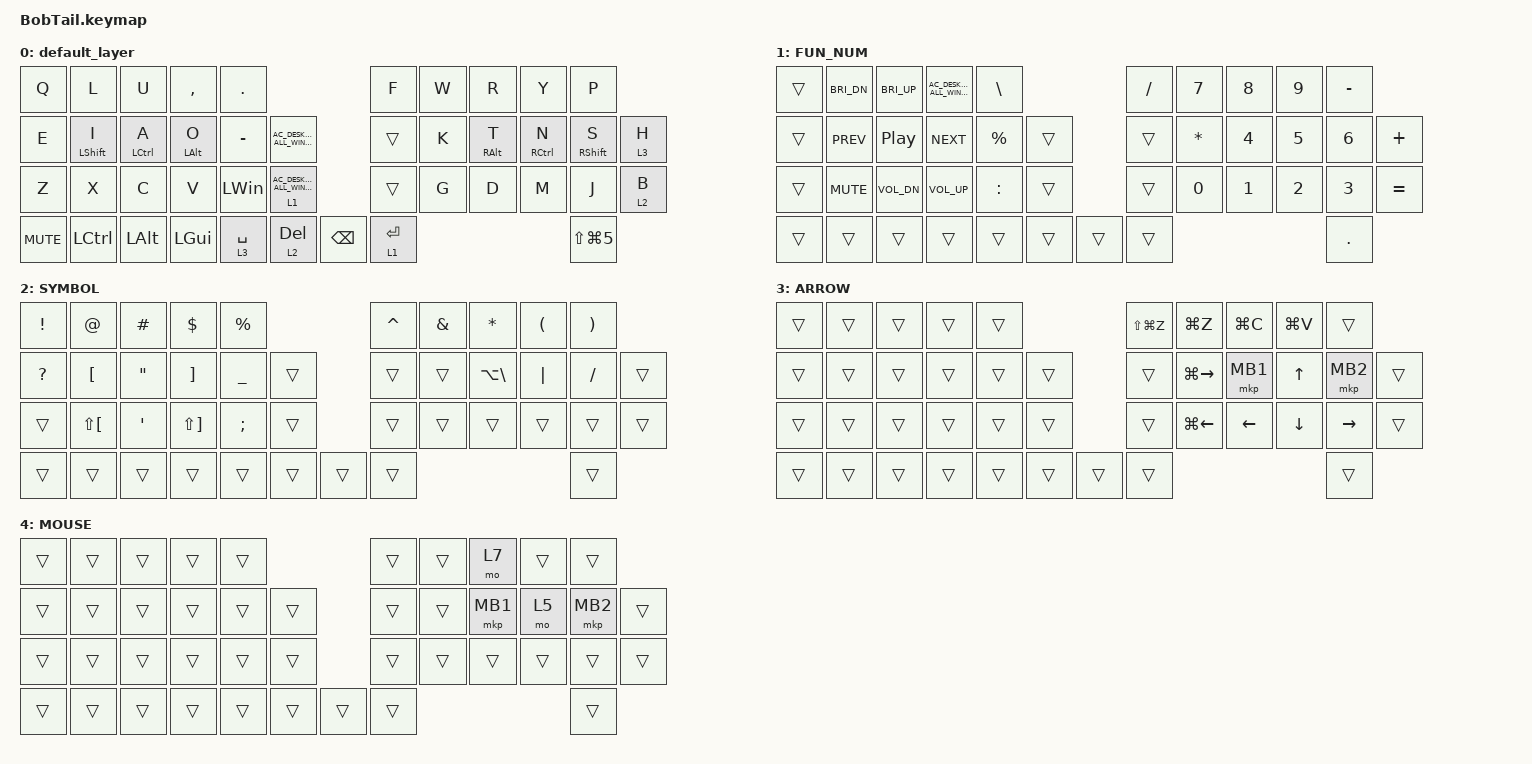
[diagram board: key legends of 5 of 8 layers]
#include <behaviors.dtsi>
#include <dt-bindings/zmk/bt.h>
#include <dt-bindings/zmk/keys.h>
#include <dt-bindings/zmk/pointing.h>

#define MOUSE 4
#define SCROLL 5
#define NUM 6
#define ZMK_POINTING_DEFAULT_SCRL_VAL 80

&mt {
    flavor = "balanced";
    quick-tap-ms = <0>;
};

/ {
    combos {
        compatible = "zmk,combos";

        lang2 {
            bindings = <&kp LANG2>;
            key-positions = <13 12>;
        };

        lang1 {
            bindings = <&kp LANG1>;
            key-positions = <18 19>;
        };

        esc {
            bindings = <&kp ESC>;
            key-positions = <0 1>;
        };

        tab {
            bindings = <&kp TAB>;
            key-positions = <10 11>;
        };

        Bluetooth {
            bindings = <&mo 6>;
            key-positions = <34 35>;
        };
    };

    behaviors {

        encoder_msc_down_up: encoder_msc_down_up {
            compatible = "zmk,behavior-sensor-rotate";
            label = "ENCODER_MSC_DOWN_UP";
            #sensor-binding-cells = <0>;
            bindings = <&msc SCRL_DOWN>, <&msc SCRL_UP>;
            tap-ms = <20>;
        };

        encoder_scroll_v: encoder_scroll_v {
            compatible = "zmk,behavior-sensor-rotate";
            label = "ENCODER_SCROLL_V";
            #sensor-binding-cells = <0>;
            bindings = <&msc SCRL_DOWN>, <&msc SCRL_UP>;
            tap-ms = <20>;
        };

        encoder_volume: encoder_volume {
            compatible = "zmk,behavior-sensor-rotate";
            label = "ENCODER_VOLUME";
            #sensor-binding-cells = <0>;
            bindings = <&kp C_VOL_UP>, <&kp C_VOL_DN>;
            tap-ms = <20>;
        };

        encoder_win_zoom: encoder_win_zoom {
            compatible = "zmk,behavior-sensor-rotate";
            label = "ENCODER_WIN_ZOOM";
            #sensor-binding-cells = <0>;
            /* 右回し→⌘-、左回し→⌘; */
            bindings = <&kp LG(MINUS)>, <&kp LG(SEMI)>;
            tap-ms = <20>;
        };

        encoder_scroll_h: encoder_scroll_h {
            compatible = "zmk,behavior-sensor-rotate";
            label = "ENCODER_SCROLL_H";
            #sensor-binding-cells = <0>;
            /* 右回し→左、左回し→右 */
            /* 縦スクロール80に対して横スクロール160 */
            bindings = <&msc MOVE_X(-160)>, <&msc MOVE_X(160)>;
            tap-ms = <20>;
        };
    };

    keymap {
        compatible = "zmk,keymap";

        default_layer {
            bindings = <
&kp Q       &kp L             &kp U         &kp COMMA       &kp PERIOD                                     &kp F        &kp W            &kp R        &kp Y              &kp P
&kp E       &mt LEFT_SHIFT I  &mt LCTRL A   &mt LEFT_ALT O  &kp MINUS     &kp C_AC_DESKTOP_SHOW_ALL_WINDOWS   &trans         &kp K        &mt RIGHT_ALT T  &mt RCTRL N  &mt RIGHT_SHIFT S  &lt 3 H
&kp Z       &kp X             &kp C         &kp V           &kp LEFT_WIN  &lt 1 C_AC_DESKTOP_SHOW_ALL_WINDOWS  &trans         &kp G        &kp D            &kp M        &kp J              &lt 2 B
&kp C_MUTE  &kp LCTRL         &kp LEFT_ALT  &kp LEFT_GUI    &lt 3 SPACE   &lt 2 DELETE      &kp BACKSPACE  &lt 1 ENTER                                                   &kp LS(LG(N5))
            >;

            sensor-bindings = <&encoder_msc_down_up>;
        };

        FUN_NUM {
            bindings = <
&trans  &kp C_BRI_DN  &kp C_BRI_UP      &kp C_AC_DESKTOP_SHOW_ALL_WINDOWS  &kp BACKSLASH                      &kp SLASH  &kp N7  &kp N8  &kp N9  &kp MINUS
&trans  &kp C_PREV    &kp C_PLAY_PAUSE  &kp C_NEXT                         &kp PRCNT      &trans      &trans  &kp ASTRK  &kp N4  &kp N5  &kp N6  &kp PLUS
&trans  &kp C_MUTE    &kp C_VOL_DN      &kp C_VOL_UP                       &kp COLON      &trans      &trans  &kp N0     &kp N1  &kp N2  &kp N3  &kp EQUAL
&trans  &trans        &trans            &trans                             &trans         &trans      &trans  &trans                             &kp DOT
            >;

            sensor-bindings = <&encoder_volume>;
        };

        SYMBOL {
            bindings = <
&kp EXCL   &kp AT        &kp HASH  &kp DLLR      &kp PRCNT                      &kp CARET  &kp AMPERSAND      &kp STAR  &kp LPAR   &kp RPAR
&kp QMARK  &kp LBKT      &kp DQT   &kp RBKT      &kp UNDER  &trans      &trans  &trans     &kp LA(BACKSLASH)  &kp PIPE  &kp SLASH  &trans
&trans     &kp LS(LBKT)  &kp SQT   &kp LS(RBKT)  &kp SEMI   &trans      &trans  &trans     &trans             &trans    &trans     &trans
&trans     &trans        &trans    &trans        &trans     &trans      &trans  &trans                                             &trans
            >;

            sensor-bindings = <&encoder_win_zoom>;
        };

        ARROW {
            bindings = <
&trans  &trans  &trans  &trans  &trans                      &kp LS(LG(Z))        &kp LG(Z)       &kp LG(C)       &kp LG(V)        &trans
&trans  &trans  &trans  &trans  &trans  &trans      &trans  &kp LG(RIGHT_ARROW)  &mkp MB1        &kp UP_ARROW    &mkp MB2         &trans
&trans  &trans  &trans  &trans  &trans  &trans      &trans  &kp LG(LEFT_ARROW)   &kp LEFT_ARROW  &kp DOWN_ARROW  &kp RIGHT_ARROW  &trans
&trans  &trans  &trans  &trans      &trans          &trans      &trans  &trans                                                                &trans
            >;

            sensor-bindings = <&encoder_scroll_h>;
        };

        MOUSE {
            bindings = <
&trans  &trans  &trans  &trans  &trans                      &trans  &trans    &mo 7   &trans    &trans
&trans  &trans  &trans  &trans  &trans  &trans      &trans  &trans  &mkp MB1  &mo 5   &mkp MB2  &trans
&trans  &trans  &trans  &trans  &trans  &trans      &trans  &trans  &trans    &trans  &trans    &trans
&trans  &trans  &trans  &trans  &trans  &trans      &trans  &trans                              &trans
            >;

            sensor-bindings = <&encoder_scroll_v>;
        };

        SCROLL {
            bindings = <
&trans  &trans  &trans  &trans  &trans                      &trans  &trans  &trans  &trans  &trans
&trans  &trans  &trans  &trans  &trans  &trans      &trans  &trans  &trans  &trans  &trans  &trans
&trans  &trans  &trans  &trans  &trans      &trans  &trans  &trans  &trans  &trans  &trans
&trans  &trans  &trans  &trans  &trans  &trans      &trans  &trans                          &trans
            >;

            sensor-bindings = <&encoder_scroll_v>;
        };

        BLUETOOTH {
            bindings = <
&trans  &trans  &trans  &trans  &trans                          &trans        &trans        &trans        &trans        &trans
&trans  &trans  &trans  &trans  &trans  &trans      &trans      &trans        &bt BT_SEL 4  &trans        &trans        &trans
&trans  &trans  &trans  &trans  &trans      &trans  &bt BT_SEL 0  &bt BT_SEL 1  &bt BT_SEL 2  &bt BT_SEL 3  &trans
&trans  &trans  &trans  &trans  &trans      &bt BT_CLR  &trans                                                  &trans
            >;

            sensor-bindings = <&encoder_scroll_v>;
        };

        X_SCROLL {
            bindings = <
&trans  &trans  &trans  &trans  &trans                      &trans  &trans  &trans  &trans  &trans
&trans  &trans  &trans  &trans  &trans  &trans      &trans  &trans  &trans  &trans  &trans  &trans
&trans  &trans  &trans  &trans  &trans      &trans  &trans  &trans  &trans  &trans  &trans
&trans  &trans  &trans  &trans  &trans  &trans      &trans  &trans                          &trans
            >;

            sensor-bindings = <&encoder_scroll_v>;
        };
    };
};
